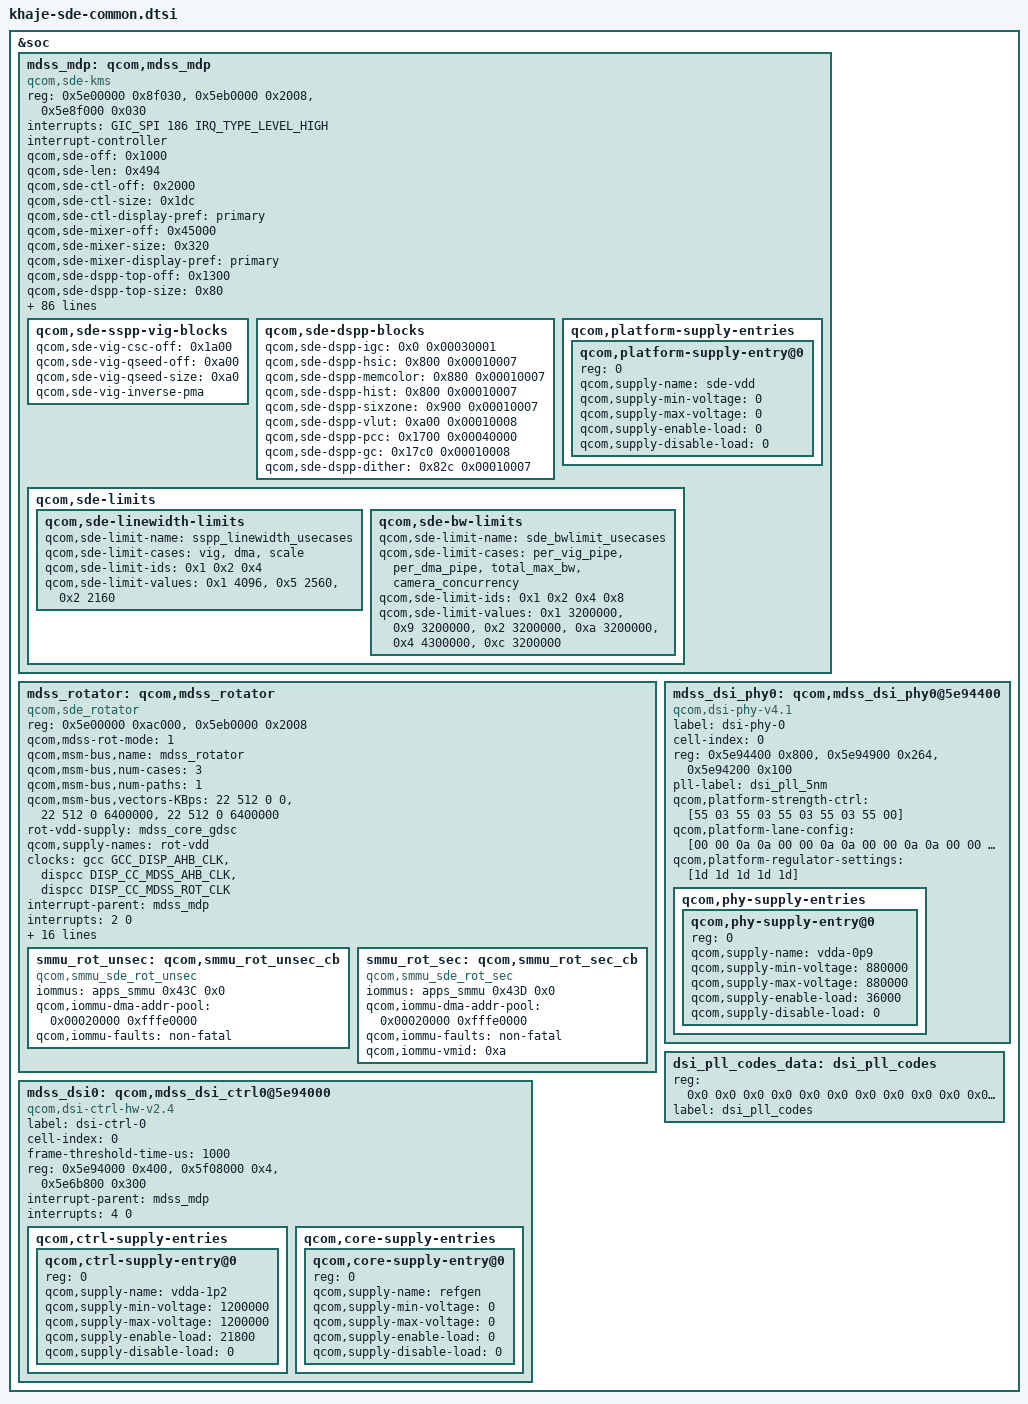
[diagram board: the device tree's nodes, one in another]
#include <dt-bindings/interrupt-controller/arm-gic.h>
#include <dt-bindings/interconnect/qcom,bengal.h>

&soc {
	mdss_mdp: qcom,mdss_mdp {
		compatible = "qcom,sde-kms";
		reg = <0x5e00000 0x8f030>,
		      <0x5eb0000 0x2008>,
		      <0x5e8f000 0x030>;

		reg-names = "mdp_phys",
			   "vbif_phys",
			   "sid_phys";

		/* interrupt config */
		interrupts = <GIC_SPI 186 IRQ_TYPE_LEVEL_HIGH>;
		interrupt-controller;
		#interrupt-cells = <1>;
	        #cooling-cells = <2>;
		#power-domain-cells = <0>;
		#list-cells = <1>;

		/* hw blocks */
		qcom,sde-off = <0x1000>;
		qcom,sde-len = <0x494>;

		qcom,sde-ctl-off = <0x2000>;
		qcom,sde-ctl-size = <0x1dc>;
		qcom,sde-ctl-display-pref = "primary";

		qcom,sde-mixer-off = <0x45000>;
		qcom,sde-mixer-size = <0x320>;
		qcom,sde-mixer-display-pref = "primary";

		qcom,sde-dspp-top-off = <0x1300>;
		qcom,sde-dspp-top-size = <0x80>;
		qcom,sde-dspp-off = <0x55000>;
		qcom,sde-dspp-size = <0x1800>;

		qcom,sde-dspp-rc-version = <0x00010000>;
		qcom,sde-dspp-rc-off = <0x15800>;
		qcom,sde-dspp-rc-size = <0x100>;
		qcom,sde-dspp-rc-mem-size = <2720>;

		qcom,sde-intf-off = <0x0 0x6b800>;
		qcom,sde-intf-size = <0x2c0>;
		qcom,sde-intf-type = "none", "dsi";
		qcom,sde-intf-tear-irq-off = <0 0x6e800>;

		qcom,sde-pp-off = <0x71000>;
		qcom,sde-pp-size = <0xd4>;

		qcom,sde-dsc-off = <0x81000>;
		qcom,sde-dsc-size = <0x140>;

		qcom,sde-dither-off = <0x30e0>;
		qcom,sde-dither-version = <0x00010000>;
		qcom,sde-dither-size = <0x20>;

		qcom,sde-sspp-type = "vig", "dma";

		qcom,sde-sspp-off = <0x5000 0x25000>;
		qcom,sde-sspp-src-size = <0x1f8>;

		qcom,sde-sspp-xin-id = <0 1>;
		qcom,sde-sspp-excl-rect = <1 1>;
		qcom,sde-sspp-smart-dma-priority = <2 1>;
		qcom,sde-smart-dma-rev = "smart_dma_v2p5";

		qcom,sde-mixer-pair-mask = <0>;

		qcom,sde-mixer-blend-op-off = <0x20 0x38 0x50 0x68 0x80 0x98
						0xb0 0xc8 0xe0 0xf8 0x110>;

		qcom,sde-mixer-stage-base-layer;

		qcom,sde-max-per-pipe-bw-kbps = <3200000 3200000>;

		qcom,sde-max-per-pipe-bw-high-kbps = <3200000 3200000>;

		/* offsets are relative to "mdp_phys + qcom,sde-off */
		qcom,sde-sspp-clk-ctrl =
				<0x2ac 0>, <0x2ac 8>;
		qcom,sde-sspp-csc-off = <0x1a00>;
		qcom,sde-csc-type = "csc-10bit";
		qcom,sde-qseed-sw-lib-rev = "qseedv3lite";
		qcom,sde-qseed-scalar-version = <0x3000>;
		qcom,sde-sspp-qseed-off = <0xa00>;
		qcom,sde-mixer-linewidth = <2048>;
		qcom,sde-sspp-linewidth = <2160>;
		qcom,sde-mixer-blendstages = <0x4>;
		qcom,sde-highest-bank-bit = <0x1>;
		qcom,sde-ubwc-version = <0x10000000>;
		qcom,sde-ubwc-swizzle = <0x7>;
		qcom,sde-ubwc-static = <0x11F>;
		qcom,sde-panic-per-pipe;
		qcom,sde-has-cdp;

		qcom,sde-has-dim-layer;
		qcom,sde-has-idle-pc;

		qcom,sde-max-bw-low-kbps = <3200000>;
		qcom,sde-max-bw-high-kbps = <4300000>;
		qcom,sde-min-core-ib-kbps = <2400000>;
		qcom,sde-min-llcc-ib-kbps = <0>;
		qcom,sde-min-dram-ib-kbps = <1600000>;
		qcom,sde-dram-channels = <1>;
		qcom,sde-num-nrt-paths = <0>;

		qcom,sde-vbif-off = <0>;
		qcom,sde-vbif-size = <0x2008>;
		qcom,sde-vbif-id = <0>;
		qcom,sde-vbif-memtype-0 = <3 3 3 3 3 3 3 3>;
		qcom,sde-vbif-memtype-1 = <3 3 3 3 3 3>;

		qcom,sde-vbif-qos-rt-remap = <3 3 4 4 5 5 6 6 3 3 4 4 5 5 6 6>;
		qcom,sde-vbif-qos-nrt-remap = <3 3 3 3 3 3 3 3 3 3 3 3 3 3 3 3>;

		/*Pending macrotile & macrotile-qseed has the same configs */

		qcom,sde-danger-lut = <0x000000ff 0x0000ffff
			0x00000000 0x00000000 0x0000ffff>;

		qcom,sde-safe-lut-linear = <0 0xfff0>;
		qcom,sde-safe-lut-macrotile = <0 0xff00>;
		/* same as safe-lut-macrotile */
		qcom,sde-safe-lut-macrotile-qseed = <0 0xff00>;
		qcom,sde-safe-lut-nrt = <0 0xffff>;

		qcom,sde-qos-lut-linear = <0 0x00112222 0x22335777>;
		qcom,sde-qos-lut-macrotile = <0 0x00112233 0x44556677>;
		qcom,sde-qos-lut-macrotile-qseed = <0 0x00112233 0x66777777>;
		qcom,sde-qos-lut-nrt = <0 0x00000000 0x00000000>;

		qcom,sde-cdp-setting = <1 1>, <1 0>;

		qcom,sde-qos-cpu-mask = <0x3>;
		qcom,sde-qos-cpu-dma-latency = <300>;
		qcom,sde-qos-cpu-irq-latency = <300>;

		qcom,sde-secure-sid-mask = <0x0000421>;
		qcom,sde-num-mnoc-ports = <1>;
		qcom,sde-axi-bus-width = <16>;


	        qcom,sde-reg-bus,vectors-KBps = <0 0>,
                                <0 76800>,
                                <0 150000>,
                                <0 300000>;

		qcom,sde-sspp-vig-blocks {
			qcom,sde-vig-csc-off = <0x1a00>;
			qcom,sde-vig-qseed-off = <0xa00>;
			qcom,sde-vig-qseed-size = <0xa0>;
			qcom,sde-vig-inverse-pma;
		};

		qcom,sde-dspp-blocks {
			qcom,sde-dspp-igc = <0x0 0x00030001>;
			qcom,sde-dspp-hsic = <0x800 0x00010007>;
			qcom,sde-dspp-memcolor = <0x880 0x00010007>;
			qcom,sde-dspp-hist = <0x800 0x00010007>;
			qcom,sde-dspp-sixzone= <0x900 0x00010007>;
			qcom,sde-dspp-vlut = <0xa00 0x00010008>;
			qcom,sde-dspp-pcc = <0x1700 0x00040000>;
			qcom,sde-dspp-gc = <0x17c0 0x00010008>;
			qcom,sde-dspp-dither = <0x82c 0x00010007>;
		};

		qcom,platform-supply-entries {
			#address-cells = <1>;
			#size-cells = <0>;

			qcom,platform-supply-entry@0 {
				reg = <0>;
				qcom,supply-name = "sde-vdd";
				qcom,supply-min-voltage = <0>;
				qcom,supply-max-voltage = <0>;
				qcom,supply-enable-load = <0>;
				qcom,supply-disable-load = <0>;
			};
		};

		qcom,sde-limits {
			qcom,sde-linewidth-limits {
				qcom,sde-limit-name = "sspp_linewidth_usecases";
				qcom,sde-limit-cases = "vig", "dma", "scale";
				qcom,sde-limit-ids= <0x1 0x2 0x4>;
				qcom,sde-limit-values = <0x1 4096>,
							<0x5 2560>,
							<0x2 2160>;
			};

			qcom,sde-bw-limits {
				qcom,sde-limit-name = "sde_bwlimit_usecases";
				qcom,sde-limit-cases = "per_vig_pipe",
							"per_dma_pipe",
							"total_max_bw",
							"camera_concurrency";
				qcom,sde-limit-ids = <0x1 0x2 0x4 0x8>;
				qcom,sde-limit-values = <0x1 3200000>,
							<0x9 3200000>,
							<0x2 3200000>,
							<0xa 3200000>,
							<0x4 4300000>,
							<0xc 3200000>;
			};
		};
	};

        mdss_rotator: qcom,mdss_rotator {
                compatible = "qcom,sde_rotator";
                reg = <0x5e00000 0xac000>,
                      <0x5eb0000 0x2008>;
                reg-names = "mdp_phys",
                            "rot_vbif_phys";

                #list-cells = <1>;

                qcom,mdss-rot-mode = <1>;

                /* Bus Scale Settings */
                qcom,msm-bus,name = "mdss_rotator";
                qcom,msm-bus,num-cases = <3>;
                qcom,msm-bus,num-paths = <1>;
                qcom,msm-bus,vectors-KBps =
                        <22 512 0 0>,
                        <22 512 0 6400000>,
                        <22 512 0 6400000>;

                rot-vdd-supply = <&mdss_core_gdsc>;
                qcom,supply-names = "rot-vdd";

                clocks =
                        <&gcc GCC_DISP_AHB_CLK>,
                        <&dispcc DISP_CC_MDSS_AHB_CLK>,
                        <&dispcc DISP_CC_MDSS_ROT_CLK>;
                clock-names = "gcc_iface",
                        "iface_clk", "rot_clk";

                interrupt-parent = <&mdss_mdp>;
                interrupts = <2 0>;

                power-domains = <&mdss_mdp>;
                /*Offline rotator RT setting */
                qcom,mdss-rot-parent = <&mdss_mdp 0>;
                qcom,mdss-rot-xin-id = <10 11>;

                /* Offline rotator QoS setting */
                qcom,mdss-rot-vbif-qos-setting = <3 3 3 3 3 3 3 3>;
                qcom,mdss-rot-cdp-setting = <1 1>;
                qcom,mdss-rot-qos-lut = <0x0 0x0 0x0 0x0>;
                qcom,mdss-rot-danger-lut = <0x0 0x0>;
                qcom,mdss-rot-safe-lut = <0x0000ffff 0x0000ffff>;

                qcom,mdss-default-ot-rd-limit = <32>;
                qcom,mdss-default-ot-wr-limit = <32>;

                qcom,mdss-sbuf-headroom = <20>;

                /* reg bus scale settings */
		interconnects = <&mmrt_virt MASTER_MDP_PORT0 &bimc SLAVE_EBI_CH0>,
				<&bimc MASTER_AMPSS_M0
					&config_noc SLAVE_DISPLAY_CFG>;
		interconnect-names = "qcom,rot-data-bus0",
				"qcom,sde-reg-bus";
		qcom,sde-reg-bus,vectors-KBps = <0 0>,
				<0 76800>;
                smmu_rot_unsec: qcom,smmu_rot_unsec_cb {
                        compatible = "qcom,smmu_sde_rot_unsec";
                        iommus = <&apps_smmu 0x43C 0x0>;
                        qcom,iommu-dma-addr-pool = <0x00020000 0xfffe0000>;
                        qcom,iommu-faults = "non-fatal";
                };

                smmu_rot_sec: qcom,smmu_rot_sec_cb {
                        compatible = "qcom,smmu_sde_rot_sec";
                        iommus = <&apps_smmu 0x43D 0x0>;
                        qcom,iommu-dma-addr-pool = <0x00020000 0xfffe0000>;
                        qcom,iommu-faults = "non-fatal";
                        qcom,iommu-vmid = <0xa>;
                };
	};

	mdss_dsi0: qcom,mdss_dsi_ctrl0@5e94000 {
		compatible = "qcom,dsi-ctrl-hw-v2.4";
		label = "dsi-ctrl-0";
		cell-index = <0>;
		frame-threshold-time-us = <1000>;
		reg =   <0x5e94000 0x400>,
			<0x5f08000 0x4>,
			<0x5e6b800 0x300>;
		reg-names = "dsi_ctrl", "disp_cc_base", "mdp_intf_base";
		interrupt-parent = <&mdss_mdp>;
		interrupts = <4 0>;

		qcom,ctrl-supply-entries {
			#address-cells = <1>;
			#size-cells = <0>;

			qcom,ctrl-supply-entry@0 {
				reg = <0>;
				qcom,supply-name = "vdda-1p2";
				qcom,supply-min-voltage = <1200000>;
				qcom,supply-max-voltage = <1200000>;
				qcom,supply-enable-load = <21800>;
				qcom,supply-disable-load = <0>;
			};
		};

		qcom,core-supply-entries {
			#address-cells = <1>;
			#size-cells = <0>;

			qcom,core-supply-entry@0 {
				reg = <0>;
				qcom,supply-name = "refgen";
				qcom,supply-min-voltage = <0>;
				qcom,supply-max-voltage = <0>;
				qcom,supply-enable-load = <0>;
				qcom,supply-disable-load = <0>;
			};
		};
	};

	mdss_dsi_phy0: qcom,mdss_dsi_phy0@5e94400 {
		compatible = "qcom,dsi-phy-v4.1";
		label = "dsi-phy-0";
		cell-index = <0>;
                #clock-cells = <1>;
		reg = <0x5e94400 0x800>,
			<0x5e94900 0x264>,
			<0x5e94200 0x100>;
		reg-names = "dsi_phy", "pll_base", "dyn_refresh_base";
		pll-label = "dsi_pll_5nm";
		qcom,platform-strength-ctrl = [55 03
						55 03
						55 03
						55 03
						55 00];
		qcom,platform-lane-config = [00 00 0a 0a
						00 00 0a 0a
						00 00 0a 0a
						00 00 0a 0a
						00 00 8a 8a];
		qcom,platform-regulator-settings = [1d 1d 1d 1d 1d];
		qcom,phy-supply-entries {
			#address-cells = <1>;
			#size-cells = <0>;
			qcom,phy-supply-entry@0 {
				reg = <0>;
				qcom,supply-name = "vdda-0p9";
				qcom,supply-min-voltage = <880000>;
				qcom,supply-max-voltage = <880000>;
				qcom,supply-enable-load = <36000>;
				qcom,supply-disable-load = <0>;
			};
		};
	};

        dsi_pll_codes_data:dsi_pll_codes {
                reg = <0x0 0x0 0x0 0x0 0x0 0x0 0x0 0x0 0x0 0x0 0x0 0x0 0x0 0x0 0x0 0x0
                        0x0 0x0 0x0 0x0 0x0 0x0 0x0 0x0 0x0 0x0 0x0 0x0 0x0 0x0 0x0 0x0
                        0x0 0x0 0x0 0x0 0x0 0x0 0x0 0x0 0x0 0x0 0x0 0x0 0x0 0x0 0x0 0x0
                        0x0 0x0 0x0 0x0 0x0 0x0 0x0 0x0 0x0 0x0 0x0 0x0 0x0 0x0 0x0 0x0
                        0x0 0x0 0x0 0x0 0x0 0x0 0x0 0x0 0x0 0x0 0x0 0x0 0x0 0x0 0x0 0x0
                        0x0 0x0 0x0 0x0 0x0 0x0 0x0 0x0 0x0 0x0 0x0 0x0 0x0 0x0 0x0 0x0
                        0x0 0x0 0x0 0x0 0x0 0x0 0x0 0x0 0x0 0x0 0x0 0x0 0x0 0x0 0x0 0x0
                        0x0 0x0 0x0 0x0 0x0 0x0 0x0 0x0 0x0 0x0 0x0 0x0 0x0 0x0 0x0 0x0>;
                label = "dsi_pll_codes";
        };
};
